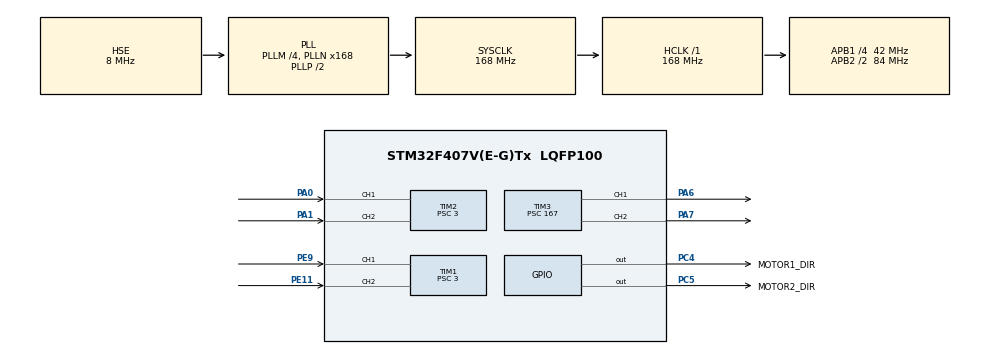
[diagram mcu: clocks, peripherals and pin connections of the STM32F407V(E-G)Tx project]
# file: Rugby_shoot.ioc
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Mcu.Family=STM32F4
Mcu.Name=STM32F407V(E-G)Tx
Mcu.Package=LQFP100
NVIC.PriorityGroup=NVIC_PRIORITYGROUP_4
NVIC.TIM3_IRQn=true\:0\:0\:false\:false\:true\:true\:true
NVIC.TIM4_IRQn=true\:0\:0\:false\:false\:true\:true\:true
PA0-WKUP.Signal=S_TIM2_CH1_ETR
PA1.Signal=S_TIM2_CH2
PA6.Signal=S_TIM3_CH1
PA7.Signal=S_TIM3_CH2
PC4.GPIO_Label=MOTOR1_DIR
PC4.GPIO_Speed=GPIO_SPEED_FREQ_HIGH
PC4.Signal=GPIO_Output
PC5.GPIO_Label=MOTOR2_DIR
PC5.GPIO_Speed=GPIO_SPEED_FREQ_HIGH
PC5.Signal=GPIO_Output
PE11.Signal=S_TIM1_CH2
PE9.Signal=S_TIM1_CH1
PH0-OSC_IN.Mode=HSE-External-Oscillator
PH0-OSC_IN.Signal=RCC_OSC_IN
PH1-OSC_OUT.Mode=HSE-External-Oscillator
PH1-OSC_OUT.Signal=RCC_OSC_OUT
ProjectManager.HeapSize=0x200
ProjectManager.StackSize=0x400
ProjectManager.TargetToolchain=MDK-ARM V5
RCC.48MHZClocksFreq_Value=84000000
RCC.AHBFreq_Value=168000000
RCC.APB1CLKDivider=RCC_HCLK_DIV4
RCC.APB1Freq_Value=42000000
RCC.APB1TimFreq_Value=84000000
RCC.APB2CLKDivider=RCC_HCLK_DIV2
RCC.APB2Freq_Value=84000000
RCC.APB2TimFreq_Value=168000000
RCC.CortexFreq_Value=168000000
RCC.HCLKFreq_Value=168000000
RCC.HSE_VALUE=8000000
RCC.HSI_VALUE=16000000
RCC.LSE_VALUE=32768
RCC.PLLM=4
RCC.PLLN=168
RCC.PLLSourceVirtual=RCC_PLLSOURCE_HSE
RCC.SYSCLKFreq_VALUE=168000000
RCC.SYSCLKSource=RCC_SYSCLKSOURCE_PLLCLK
RCC.VCOOutputFreq_Value=336000000
SH.S_TIM1_CH1.0=TIM1_CH1,Encoder_Interface
SH.S_TIM1_CH2.0=TIM1_CH2,Encoder_Interface
SH.S_TIM2_CH1_ETR.0=TIM2_CH1,Encoder_Interface
SH.S_TIM2_CH2.0=TIM2_CH2,Encoder_Interface
SH.S_TIM3_CH1.0=TIM3_CH1,PWM Generation1 CH1
SH.S_TIM3_CH2.0=TIM3_CH2,PWM Generation2 CH2
TIM1.EncoderMode=TIM_ENCODERMODE_TI12
TIM1.IC1Filter=15
TIM1.IC2Filter=15
TIM1.Period=65535
TIM1.Prescaler=3
TIM2.EncoderMode=TIM_ENCODERMODE_TI12
TIM2.IC1Filter=15
TIM2.IC2Filter=15
TIM2.Period=65535
TIM2.Prescaler=3
TIM3.Channel-PWM\ Generation1\ CH1=TIM_CHANNEL_1
TIM3.Channel-PWM\ Generation2\ CH2=TIM_CHANNEL_2
TIM3.Period=9999
TIM3.Prescaler=167
TIM4.Period=999
TIM4.Prescaler=167
VP_TIM3_VS_ClockSourceINT.Mode=Internal
VP_TIM4_VS_ClockSourceINT.Mode=Internal
board=custom

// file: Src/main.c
/* USER CODE BEGIN Header */
/**
  ******************************************************************************
  * @file           : main.c
  * @brief          : Main program body
  ******************************************************************************
  * @attention
  *
  * <h2><center>&copy; Copyright (c) 2019 STMicroelectronics.
  * All rights reserved.</center></h2>
  *
  * This software component is licensed by ST under BSD 3-Clause license,
  * the "License"; You may not use this file except in compliance with the
  * License. You may obtain a copy of the License at:
  *                        opensource.org/licenses/BSD-3-Clause
  *
  ******************************************************************************
  */
/* USER CODE END Header */

#include "main.h"
#include "tim.h"
#include "gpio.h"

void SystemClock_Config(void);
/* USER CODE BEGIN PFP */
uint16_t data = 0;
extern float true_speed;

/* USER CODE END PFP */

int main(void)
{

  /* MCU Configuration--------------------------------------------------------*/

  /* Reset of all peripherals, Initializes the Flash interface and the Systick. */
  HAL_Init();

  /* Configure the system clock */
  SystemClock_Config();

  /* Initialize all configured peripherals */
  MX_GPIO_Init();
  MX_TIM1_Init();
  MX_TIM2_Init();
  MX_TIM3_Init();
  MX_TIM4_Init();
  /* USER CODE BEGIN 2 */
	HAL_TIM_PWM_Start(&htim3, TIM_CHANNEL_1);
	HAL_TIM_PWM_Start(&htim3, TIM_CHANNEL_2);
	HAL_TIM_Encoder_Start(&htim1, TIM_CHANNEL_ALL);
	HAL_TIM_Encoder_Start(&htim2, TIM_CHANNEL_ALL);
	HAL_TIM_Base_Start_IT(&htim4);    //1ms中断
	HAL_TIM_Base_Start_IT(&htim3);    //10MS中断
//

  /* USER CODE END 2 */

  /* Infinite loop */
  while (1)
  {

  }
}

void SystemClock_Config(void)
{
  RCC_OscInitTypeDef RCC_OscInitStruct = {0};
  RCC_ClkInitTypeDef RCC_ClkInitStruct = {0};

  /** Configure the main internal regulator output voltage
  */
  __HAL_RCC_PWR_CLK_ENABLE();
  __HAL_PWR_VOLTAGESCALING_CONFIG(PWR_REGULATOR_VOLTAGE_SCALE1);
  /** Initializes the CPU, AHB and APB busses clocks
  */
  RCC_OscInitStruct.OscillatorType = RCC_OSCILLATORTYPE_HSE;
  RCC_OscInitStruct.HSEState = RCC_HSE_ON;
  RCC_OscInitStruct.PLL.PLLState = RCC_PLL_ON;
  RCC_OscInitStruct.PLL.PLLSource = RCC_PLLSOURCE_HSE;
  RCC_OscInitStruct.PLL.PLLM = 4;
  RCC_OscInitStruct.PLL.PLLN = 168;
  RCC_OscInitStruct.PLL.PLLP = RCC_PLLP_DIV2;
  RCC_OscInitStruct.PLL.PLLQ = 4;
  if (HAL_RCC_OscConfig(&RCC_OscInitStruct) != HAL_OK)
  {
    Error_Handler();
  }
  /** Initializes the CPU, AHB and APB busses clocks
  */
  RCC_ClkInitStruct.ClockType = RCC_CLOCKTYPE_HCLK|RCC_CLOCKTYPE_SYSCLK
                              |RCC_CLOCKTYPE_PCLK1|RCC_CLOCKTYPE_PCLK2;
  RCC_ClkInitStruct.SYSCLKSource = RCC_SYSCLKSOURCE_PLLCLK;
  RCC_ClkInitStruct.AHBCLKDivider = RCC_SYSCLK_DIV1;
  RCC_ClkInitStruct.APB1CLKDivider = RCC_HCLK_DIV4;
  RCC_ClkInitStruct.APB2CLKDivider = RCC_HCLK_DIV2;

  if (HAL_RCC_ClockConfig(&RCC_ClkInitStruct, FLASH_LATENCY_5) != HAL_OK)
  {
    Error_Handler();
  }
}

void Error_Handler(void)
{
}

/************************ (C) COPYRIGHT STMicroelectronics *****END OF FILE****/
